# STM32F0xx register map
File version: 1.0
Registers are 32-bit, read-write, reset 0x0 unless marked. A register's access mark holds for its fields unless they carry their own. Offsets are from the block's base; [hi:lo] are bit positions.

## DAC — Digital-to-analog converter
Base 0x40007400
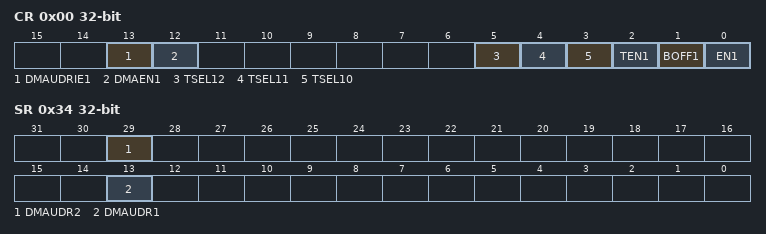
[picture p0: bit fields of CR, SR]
0x00 CR — control register
  [13] DMAUDRIE1 — DAC channel1 DMA Underrun Interrupt enable
  [12] DMAEN1 — DAC channel1 DMA enable
  [5] TSEL12 — DAC channel1 trigger selection
  [4] TSEL11 — DAC channel1 trigger selection
  [3] TSEL10 — DAC channel1 trigger selection
  [2] TEN1 — DAC channel1 trigger enable
  [1] BOFF1 — DAC channel1 output buffer disable
  [0] EN1 — DAC channel1 enable
0x04 SWTRIGR wo — software trigger register
  [0] SWTRIG1 — DAC channel1 software trigger
0x08 DHR12R1 — channel1 12-bit right-aligned data holding register
  [11:0] DACC1DHR — DAC channel1 12-bit right-aligned data
0x0C DHR12L1 — channel1 12-bit left aligned data holding register
  [15:4] DACC1DHR — DAC channel1 12-bit left-aligned data
0x10 DHR8R1 — channel1 8-bit right aligned data holding register
  [7:0] DACC1DHR — DAC channel1 8-bit right-aligned data
0x2C DOR1 ro — channel1 data output register
  [11:0] DACC1DOR — DAC channel1 data output
0x34 SR — status register
  [29] DMAUDR2 — DAC channel2 DMA underrun flag
  [13] DMAUDR1 — DAC channel1 DMA underrun flag

## PWR — Power control
Base 0x40007000
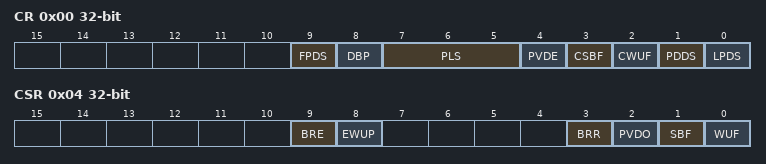
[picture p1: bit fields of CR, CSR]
0x00 CR — power control register
  [9] FPDS — Flash power down in Stop mode
  [8] DBP — Disable backup domain write protection
  [7:5] PLS — PVD level selection
  [4] PVDE — Power voltage detector enable
  [3] CSBF — Clear standby flag
  [2] CWUF — Clear wakeup flag
  [1] PDDS — Power down deepsleep
  [0] LPDS — Low-power deep sleep
0x04 CSR access per field — power control/status register
  [9] BRE rw — Backup regulator enable
  [8] EWUP rw — Enable WKUP pin
  [3] BRR ro — Backup regulator ready
  [2] PVDO ro — PVD output
  [1] SBF ro — Standby flag
  [0] WUF ro — Wakeup flag

## IWDG — Independent watchdog
Base 0x40003000
0x00 KR wo — Key register
  [15:0] KEY — Key value
0x04 PR — Prescaler register
  [2:0] PR — Prescaler divider
0x08 RLR reset 0xFFF — Reload register
  [11:0] RL — Watchdog counter reload value
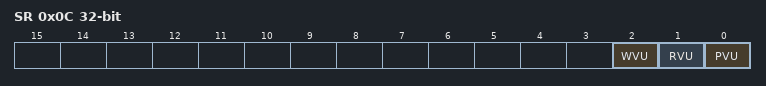
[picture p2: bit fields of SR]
0x0C SR ro — Status register
  [2] WVU — Watchdog counter window value update
  [1] RVU — Watchdog counter reload value update
  [0] PVU — Watchdog prescaler value update
0x10 WINR reset 0xFFF — Window register
  [11:0] WIN — Watchdog counter window value

## WWDG — Window watchdog
Base 0x40002C00
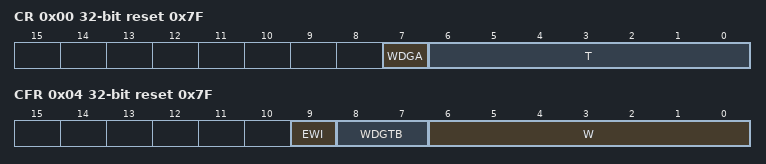
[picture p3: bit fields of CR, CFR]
0x00 CR reset 0x7F — Control register
  [7] WDGA — Activation bit
  [6:0] T — 7-bit counter
0x04 CFR reset 0x7F — Configuration register
  [9] EWI — Early wakeup interrupt
  [8:7] WDGTB — Timer base
  [6:0] W — 7-bit window value
0x08 SR — Status register
  [0] EWIF — Early wakeup interrupt flag

## TIM14 — General-purpose-timers
Base 0x40002000
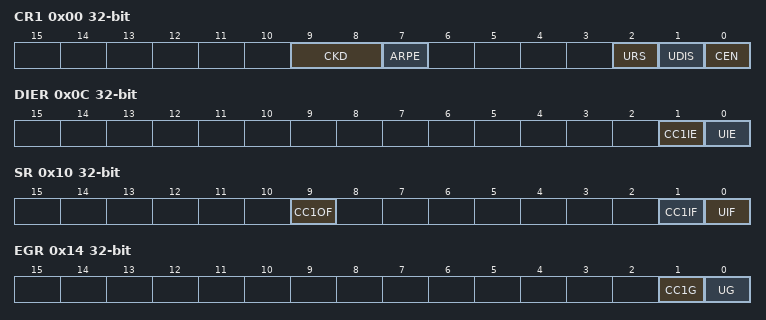
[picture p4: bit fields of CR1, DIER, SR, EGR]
0x00 CR1 — control register 1
  [9:8] CKD — Clock division
  [7] ARPE — Auto-reload preload enable
  [2] URS — Update request source
  [1] UDIS — Update disable
  [0] CEN — Counter enable
    0=disabled (Disable the Rising trigger.); 1=enabled (Enable the Rising trigger.)
0x0C DIER — DMA/Interrupt enable register
  [1] CC1IE — Capture/Compare 1 interrupt enable
  [0] UIE — Update interrupt enable
0x10 SR — status register
  [9] CC1OF — Capture/Compare 1 overcapture flag
  [1] CC1IF — Capture/compare 1 interrupt flag
  [0] UIF — Update interrupt flag
0x14 EGR wo — event generation register
  [1] CC1G — Capture/compare 1 generation
  [0] UG — Update generation
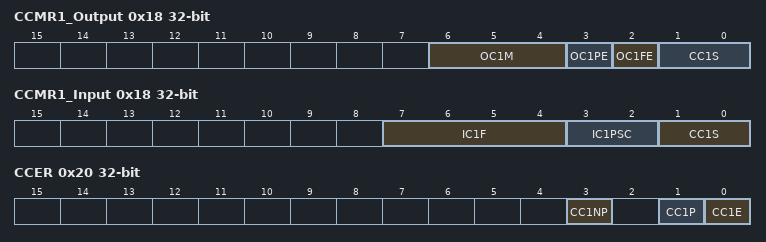
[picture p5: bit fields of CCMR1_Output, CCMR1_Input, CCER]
0x18 CCMR1_Output — capture/compare mode register (output mode)
  [6:4] OC1M — Output Compare 1 mode
  [3] OC1PE — Output Compare 1 preload enable
  [2] OC1FE — Output compare 1 fast enable
  [1:0] CC1S — Capture/Compare 1 selection
0x18 CCMR1_Input (alternate view of CCMR1_Output) — capture/compare mode register (input mode)
  [7:4] IC1F — Input capture 1 filter
  [3:2] IC1PSC — Input capture 1 prescaler
  [1:0] CC1S — Capture/Compare 1 selection
0x20 CCER — capture/compare enable register
  [3] CC1NP — Capture/Compare 1 output Polarity
  [1] CC1P — Capture/Compare 1 output Polarity
  [0] CC1E — Capture/Compare 1 output enable
0x24 CNT — counter
  [15:0] CNT — counter value
0x28 PSC — prescaler
  [15:0] PSC — Prescaler value
0x2C ARR — auto-reload register
  [15:0] ARR — Auto-reload value
0x34 CCR1 — capture/compare register 1
  [15:0] CCR1 — Capture/Compare 1 value
0x50 OR — option register
  [1:0] RMP — Timer input 1 remap
